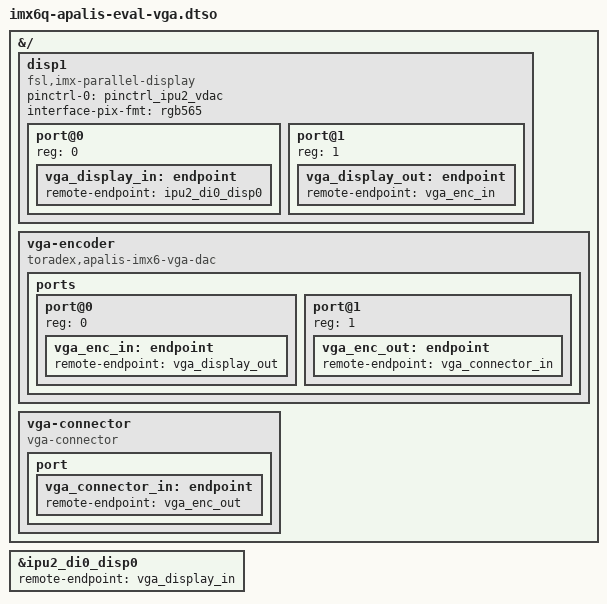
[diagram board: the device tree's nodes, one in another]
// SPDX-License-Identifier: GPL-2.0-only OR MIT
/*
 * Copyright (c) Toradex
 *
 * VGA output connected to a parallel RGB LCD interface through a
 * non-programmable video DAC with a VGA connector.
 *
 * The VGA output is available on the Apalis Evaluation Board without VESA DDC
 * I2C signals.
 */

/dts-v1/;
/plugin/;

&{/} {
	disp1 {
		compatible = "fsl,imx-parallel-display";
		pinctrl-names = "default";
		pinctrl-0 = <&pinctrl_ipu2_vdac>;
		#address-cells = <1>;
		#size-cells = <0>;
		interface-pix-fmt = "rgb565";

		port@0 {
			reg = <0>;

			vga_display_in: endpoint {
				remote-endpoint = <&ipu2_di0_disp0>;
			};
		};

		port@1 {
			reg = <1>;

			vga_display_out: endpoint {
				remote-endpoint = <&vga_enc_in>;
			};
		};
	};

	vga-encoder {
		compatible = "toradex,apalis-imx6-vga-dac";

		ports {
			#address-cells = <1>;
			#size-cells = <0>;

			port@0 {
				reg = <0>;

				vga_enc_in: endpoint {
					remote-endpoint = <&vga_display_out>;
				};
			};

			port@1 {
				reg = <1>;

				vga_enc_out: endpoint {
					remote-endpoint = <&vga_connector_in>;
				};
			};
		};
	};

	vga-connector {
		compatible = "vga-connector";

		port {
			vga_connector_in: endpoint {
				remote-endpoint = <&vga_enc_out>;
			};
		};
	};
};

&ipu2_di0_disp0 {
	remote-endpoint = <&vga_display_in>;
};
